# ATtiny841 register map
Vendor: Atmel; File version: 1.0
CPU: other r0p0, little endian, no MPU, no FPU, 4 interrupt priority bits
Registers are 8-bit, read-write, reset 0x0 unless marked. A register's access mark holds for its fields unless they carry their own. Offsets are from the block's base; [hi:lo] are bit positions; {n}, {i} and the like mark numbered series.

## EEPROM
Base 0x0080003C
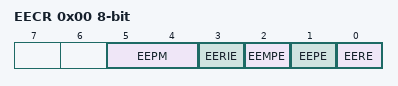
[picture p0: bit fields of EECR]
0x00 EECR — EEPROM Control Register
  [5:4] EEPM — EEPROM Programming Mode Bits
    0=ERASE_AND_WRITE_IN_ONE_OPERATION; 1=ERASE_ONLY; 2=WRITE_ONLY
  [3] EERIE — EEPROM Ready Interrupt Enable
  [2] EEMPE — EEPROM Master Write Enable
  [1] EEPE — EEPROM Write Enable
  [0] EERE — EEPROM Read Enable
0x01 EEDR — EEPROM Data Register
0x02 EEAR 16-bit (reset mask 0xFF) — EEPROM Address Register Bytes

## EXINT — External Interrupts
Base 0x00800032
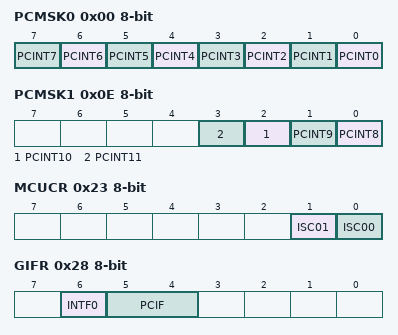
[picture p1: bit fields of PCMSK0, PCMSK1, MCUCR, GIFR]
0x00 PCMSK0 — Pin Change Enable Mask 0
  [n] PCINT{n} (n=0..7) — Pin Change Enable Mask 0 Bit {n}
0x0E PCMSK1 — Pin Change Enable Mask 1
  [n-8] PCINT{n} (n=8..11) — Pin Change Enable Mask 1 Bit {n-8}
0x23 MCUCR — MCU Control Register
  [1] ISC01 — Interrupt Sense Control 0 Bit 1
  [0] ISC00 — Interrupt Sense Control 0 Bit 0
    0=LOW_LEVEL_OF_INTX
0x28 GIFR — General Interrupt Flag register (read-only for debugger)
  [6] INTF0 — External Interrupt Flag 0
  [5:4] PCIF — Pin Change Interrupt Flags
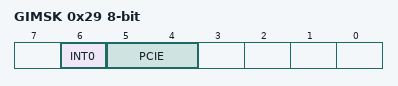
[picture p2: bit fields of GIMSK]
0x29 GIMSK — General Interrupt Mask Register
  [6] INT0 — External Interrupt Request 0 Enable
  [5:4] PCIE — Pin Change Interrupt Enables

## PORTA — I/O Port
Base 0x00800039
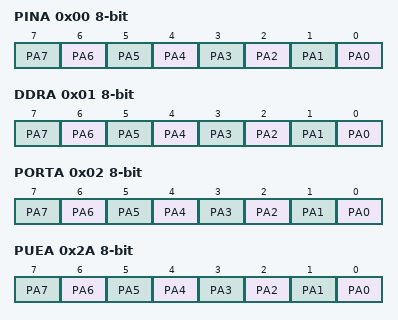
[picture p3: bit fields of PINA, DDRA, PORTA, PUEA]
0x00 PINA — Port A Input Pins
  [n] PA{n} (n=0..7) — Pin A{n}
0x01 DDRA — Data Direction Register, Port A
  [n] PA{n} (n=0..7) — Pin A{n}
0x02 PORTA — Port A Data Register
  [n] PA{n} (n=0..7) — Pin A{n}
0x2A PUEA — Pull-up Enable Control Register
  [n] PA{n} (n=0..7) — Pin A{n}
0x2B PORTCR — Port Control Register
  [0] BBMA — Break-Before-Make Mode Enable
0x31 PHDE — Port High Drive Enable Register
  [1:0] PHDEA — PortA High Drive Enable

## PORTB — I/O Port
Base 0x00800036
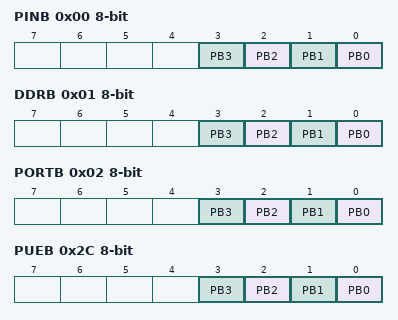
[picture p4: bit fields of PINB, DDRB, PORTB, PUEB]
0x00 PINB — Port B Data register
  [n] PB{n} (n=0..3) — Pin B{n}
0x01 DDRB — Data Direction Register, Port B
  [n] PB{n} (n=0..3) — Pin B{n}
0x02 PORTB — Input Pins, Port B
  [n] PB{n} (n=0..3) — Pin B{n}
0x2C PUEB — Pull-up Enable Control Register
  [n] PB{n} (n=0..3) — Pin B{n}
0x2E PORTCR — Port Control Register
  [1] BBMB — Break-Before-Make Mode Enable

## SPI — Serial Peripheral Interface
Base 0x00800065
0x00 REMAP — Remap Port Pins
  [1] SPIMAP — SPI Pin Mapping
0x4B SPDR — SPI Data Register (write-only for debugger)
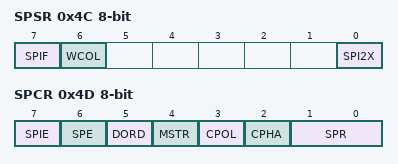
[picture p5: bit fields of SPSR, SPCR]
0x4C SPSR — SPI Status Register
  [7] SPIF — SPI Interrupt Flag
  [6] WCOL — Write Collision Flag
  [0] SPI2X — Double SPI Speed Bit
0x4D SPCR — SPI Control Register
  [7] SPIE — SPI Interrupt Enable
  [6] SPE — SPI Enable
  [5] DORD — Data Order
  [4] MSTR — Master/Slave Select
  [3] CPOL — Clock polarity
  [2] CPHA — Clock Phase
  [1:0] SPR — SPI Clock Rate Selects
    0=FCL_4; 1=FCL_16; 2=FCL_64; 3=FCL_128

## TC0 — Timer/Counter, 8-bit
Base 0x00800043
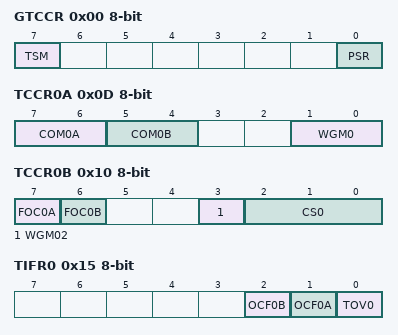
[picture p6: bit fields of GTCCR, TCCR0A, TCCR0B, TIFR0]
0x00 GTCCR — General Timer/Counter Control Register
  [7] TSM — Timer/Counter Synchronization Mode
  [0] PSR — Prescaler Reset Timer/CounterN
0x0D TCCR0A — Timer/Counter Control Register A
  [7:6] COM0A — Compare Match Output A Mode bits
  [5:4] COM0B — Compare Match Output B Mode bits
  [1:0] WGM0 — Waveform Generation Mode bits
0x0F TCNT0 — Timer/Counter0
0x10 TCCR0B — Timer/Counter Control Register B
  [7] FOC0A — Force Output Compare A
  [6] FOC0B — Force Output Compare B
  [3] WGM02 — Waveform Generation Mode bit 2
  [2:0] CS0 — Clock Select bits
    0=NO_CLOCK_SOURCE_STOPPED; 1=RUNNING_NO_PRESCALING; 2=RUNNING_CLK_8; 3=RUNNING_CLK_64; 4=RUNNING_CLK_256; 5=RUNNING_CLK_1024; 6=RUNNING_EXTCLK_TN_FALLING_EDGE; 7=RUNNING_EXTCLK_TN_RISING_EDGE
0x13 OCR0A — Timer/Counter0 Output Compare Register A
0x15 TIFR0 — Timer/Counter0 Interrupt Flag Register (read-only for debugger)
  [2] OCF0B — Timer/Counter0 Output Compare Flag B
  [1] OCF0A — Timer/Counter0 Output Compare Flag A
  [0] TOV0 — Timer/Counter0 Overflow Flag
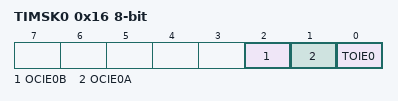
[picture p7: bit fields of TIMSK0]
0x16 TIMSK0 — Timer/Counter Interrupt Mask Register
  [2] OCIE0B — Timer/Counter0 Output Compare Match B Interrupt Enable
  [1] OCIE0A — Timer/Counter0 Output Compare Match A Interrupt Enable
  [0] TOIE0 — Timer/Counter0 Overflow Interrupt Enable
0x19 OCR0B — Timer/Counter0 Output Compare Register B
